# UPD70F3508 register map
Vendor: Renesas; Series: V850E2/Px4; File version: 1.0
CPU: other r0p0, little endian, no MPU, FPU, 4 interrupt priority bits
Registers are 8-bit, read-write, reset 0x0 unless marked. A register's access mark holds for its fields unless they carry their own. Offsets are from the block's base; [hi:lo] are bit positions.

## UARTH1 — Synchronous/Asynchronous Serial Interface H, instance 1
Base 0xFF5D0000
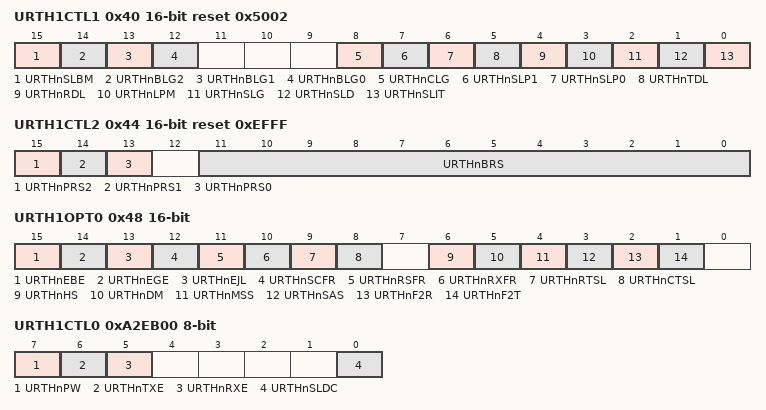
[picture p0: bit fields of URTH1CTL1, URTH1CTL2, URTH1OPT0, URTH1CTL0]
0x40 URTH1CTL1 16-bit reset 0x5002 — UARTHn Control Register 1 — data frame properties
  [15] URTHnSLBM — BF reception mode selection
  [14] URTHnBLG2 — BF bit length [2]
  [13] URTHnBLG1 — BF bit length [1]
  [12] URTHnBLG0 — BF bit length [0]
  [8] URTHnCLG — Bit length (0=7 bits, 1=8/9 bits)
  [7] URTHnSLP1 — Parity selection [1]
  [6] URTHnSLP0 — Parity selection [0]
  [5] URTHnTDL — Transmit data level inversion
  [4] URTHnRDL — Received data level inversion
  [3] URTHnLPM — Loop back mode
  [2] URTHnSLG — Stop bit count (0=1, 1=2)
  [1] URTHnSLD — Transfer direction (0=MSB-first, 1=LSB-first)
  [0] URTHnSLIT — Transmission interrupt timing
0x44 URTH1CTL2 16-bit reset 0xEFFF — UARTHn Control Register 2 — baud rate
  [15] URTHnPRS2 — Prescaler clock division [2]
  [14] URTHnPRS1 — Prescaler clock division [1]
  [13] URTHnPRS0 — Prescaler clock division [0]
  [11:0] URTHnBRS — Baud-rate clock division [11:0]
0x48 URTH1OPT0 16-bit — UARTHn Option Register 0 — optional serial features
  [15] URTHnEBE — Enhanced bit operation enable
  [14] URTHnEGE — Enhanced bit detection interrupt enable
  [13] URTHnEJL — Enhanced bit detection condition
  [12] URTHnSCFR — Noise filter for sync clock (0=enabled)
  [11] URTHnRSFR — Noise filter for handshake input (0=enabled)
  [10] URTHnRXFR — Noise filter for received data (0=enabled)
  [9] URTHnRTSL — Active level of handshake output
  [8] URTHnCTSL — Active level of handshake input
  [6] URTHnHS — Handshaking enable
  [5] URTHnDM — Delayed sampling mode
  [4] URTHnMSS — Master/slave selection
  [3] URTHnSAS — Async/sync mode select
  [2] URTHnF2R — Reception 1/2 frame
  [1] URTHnF2T — Transmission 1/2 frame
0xA2EB00 URTH1CTL0 — UARTHn Control Register 0 — basic serial-transfer control
  [7] URTHnPW — UARTHn enable
  [6] URTHnTXE — Transmission enable
  [5] URTHnRXE — Reception enable
  [0] URTHnSLDC — Data consistency check enable
0xA2EB04 URTH1OPT1 — UARTHn Option Register 1 — ID match detection
  [7] URTHnIDCN — ID match detection enable
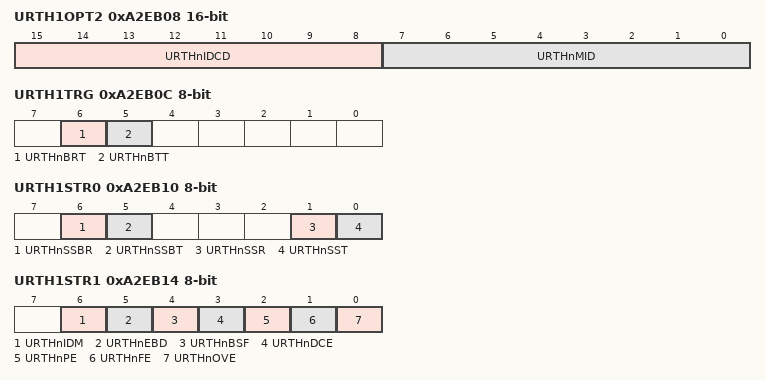
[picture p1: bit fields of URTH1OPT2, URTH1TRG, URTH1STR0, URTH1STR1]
0xA2EB08 URTH1OPT2 16-bit — UARTHn Option Register 2 — ID comparison value and mask
  [15:8] URTHnIDCD — ID value for comparison [7:0]
  [7:0] URTHnMID — ID comparison mask [7:0]
0xA2EB0C URTH1TRG — UARTHn Trigger Register — BF triggers
  [6] URTHnBRT — BF reception trigger
  [5] URTHnBTT — BF transmission trigger
0xA2EB10 URTH1STR0 ro — UARTHn Status Register 0 — current state
  [6] URTHnSSBR — BF reception enable status
  [5] URTHnSSBT — BF transmission enable status
  [1] URTHnSSR — Data reception state
  [0] URTHnSST — Data transmission state
0xA2EB14 URTH1STR1 ro — UARTHn Status Register 1 — result flags
  [6] URTHnIDM — ID match flag
  [5] URTHnEBD — Enhanced bit detection flag
  [4] URTHnBSF — BF reception success flag
  [3] URTHnDCE — Data consistency error flag
  [2] URTHnPE — Parity error flag
  [1] URTHnFE — Framing error flag
  [0] URTHnOVE — Overrun error flag
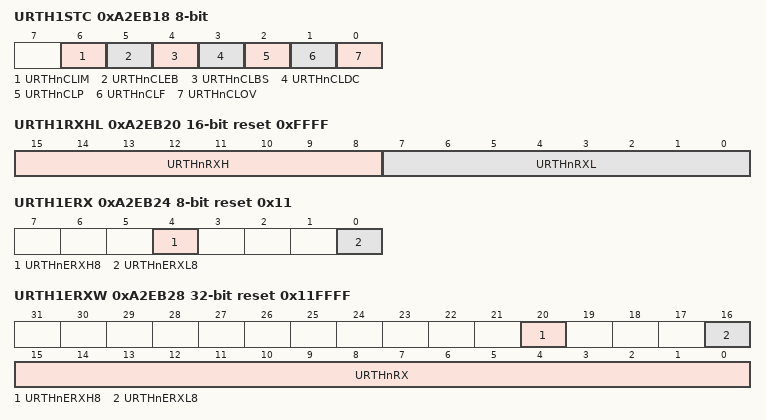
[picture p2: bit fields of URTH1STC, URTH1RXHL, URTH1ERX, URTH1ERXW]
0xA2EB18 URTH1STC — UARTHn Status Clear Register
  [6] URTHnCLIM — Clear URTHnIDM
  [5] URTHnCLEB — Clear URTHnEBD
  [4] URTHnCLBS — Clear URTHnBSF
  [3] URTHnCLDC — Clear URTHnDCE
  [2] URTHnCLP — Clear URTHnPE
  [1] URTHnCLF — Clear URTHnFE
  [0] URTHnCLOV — Clear URTHnOVE
0xA2EB1C URTH1RX ro reset 0xFF — UARTHn Receive Data Register
  [7:0] URTHnRX — Received data [7:0]
0xA2EB20 URTH1RXHL 16-bit ro reset 0xFFFF — UARTHn Receive Data Register HL
  [15:8] URTHnRXH — Received data [15:8]
  [7:0] URTHnRXL — Received data [7:0]
0xA2EB24 URTH1ERX ro reset 0x11 — UARTHn Enhanced Bit Receive Data Register
  [4] URTHnERXH8 — Enhanced bit of high frame
  [0] URTHnERXL8 — Enhanced bit of low frame
0xA2EB28 URTH1ERXW 32-bit ro reset 0x11FFFF — UARTHn Enhanced Bit Receive Word Data Register
  [20] URTHnERXH8 — Enhanced bit high frame
  [16] URTHnERXL8 — Enhanced bit low frame
  [15:0] URTHnRX — Received data [15:0]
0xA2EB2C URTH1TX reset 0xFF — UARTHn Transmit Data Register
  [7:0] URTHnTX — Transmit data [7:0]
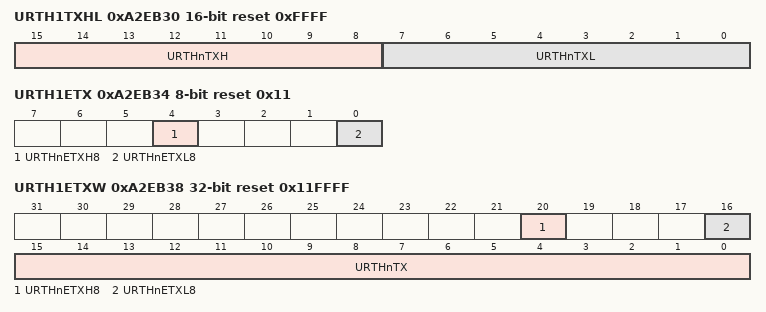
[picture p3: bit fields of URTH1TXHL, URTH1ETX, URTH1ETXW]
0xA2EB30 URTH1TXHL 16-bit reset 0xFFFF — UARTHn Transmit Data Register HL
  [15:8] URTHnTXH — Transmit data [15:8]
  [7:0] URTHnTXL — Transmit data [7:0]
0xA2EB34 URTH1ETX reset 0x11 — UARTHn Enhanced Bit Transmit Data Register
  [4] URTHnETXH8 — Enhanced bit high frame transmit
  [0] URTHnETXL8 — Enhanced bit low frame transmit
0xA2EB38 URTH1ETXW 32-bit reset 0x11FFFF — UARTHn Enhanced Bit Transmit Word Data Register
  [20] URTHnETXH8 — Enhanced bit high frame transmit
  [16] URTHnETXL8 — Enhanced bit low frame transmit
  [15:0] URTHnTX — Transmit data [15:0]
